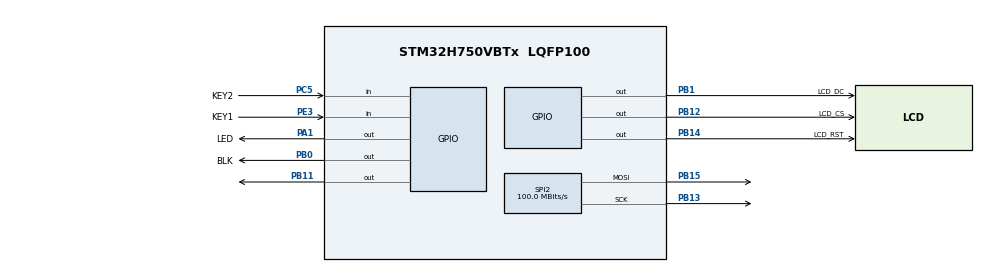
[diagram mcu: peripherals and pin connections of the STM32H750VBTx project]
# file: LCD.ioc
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Mcu.Family=STM32H7
Mcu.Name=STM32H750VBTx
Mcu.Package=LQFP100
NVIC.PriorityGroup=NVIC_PRIORITYGROUP_4
NVIC.SPI2_IRQn=true\:0\:0\:false\:false\:true\:true\:true\:true
PA1.GPIO_Label=LED
PA1.GPIO_ModeDefaultOutputPP=GPIO_MODE_OUTPUT_PP
PA1.GPIO_PuPd=GPIO_PULLUP
PA1.GPIO_Speed=GPIO_SPEED_FREQ_VERY_HIGH
PA1.PinState=GPIO_PIN_SET
PA1.Signal=GPIO_Output
PA13\ (JTMS/SWDIO).Mode=Serial_Wire
PA13\ (JTMS/SWDIO).Signal=DEBUG_JTMS-SWDIO
PA14\ (JTCK/SWCLK).Mode=Serial_Wire
PA14\ (JTCK/SWCLK).Signal=DEBUG_JTCK-SWCLK
PB0.GPIO_Label=BLK
PB0.Signal=GPIO_Output
PB1.GPIO_Label=LCD_DC
PB1.Signal=GPIO_Output
PB11.Signal=GPIO_Output
PB12.GPIO_Label=LCD_CS
PB12.Signal=GPIO_Output
PB13.GPIO_Speed=GPIO_SPEED_FREQ_VERY_HIGH
PB13.Mode=TX_Only_Simplex_Unidirect_Master
PB13.Signal=SPI2_SCK
PB14.GPIO_Label=LCD_RST
PB14.Signal=GPIO_Output
PB15.GPIO_Speed=GPIO_SPEED_FREQ_VERY_HIGH
PB15.Mode=TX_Only_Simplex_Unidirect_Master
PB15.Signal=SPI2_MOSI
PC14-OSC32_IN\ (OSC32_IN).Mode=LSE-External-Oscillator
PC14-OSC32_IN\ (OSC32_IN).Signal=RCC_OSC32_IN
PC15-OSC32_OUT\ (OSC32_OUT).Mode=LSE-External-Oscillator
PC15-OSC32_OUT\ (OSC32_OUT).Signal=RCC_OSC32_OUT
PC5.GPIO_Label=KEY2
PC5.GPIO_PuPd=GPIO_PULLUP
PC5.Signal=GPIO_Input
PE3.GPIO_Label=KEY1
PE3.GPIO_PuPd=GPIO_PULLUP
PE3.Signal=GPIO_Input
PH0-OSC_IN\ (PH0).Mode=HSE-External-Oscillator
PH0-OSC_IN\ (PH0).Signal=RCC_OSC_IN
PH1-OSC_OUT\ (PH1).Mode=HSE-External-Oscillator
PH1-OSC_OUT\ (PH1).Signal=RCC_OSC_OUT
ProjectManager.HeapSize=0x400
ProjectManager.StackSize=0x400
ProjectManager.TargetToolchain=Makefile
RCC.ADCFreq_Value=129000000
RCC.APB1Freq_Value=100000000
RCC.APB2Freq_Value=100000000
RCC.APB3Freq_Value=100000000
RCC.APB4Freq_Value=100000000
RCC.CortexFreq_Value=400000000
RCC.D1PPRE=RCC_APB3_DIV2
RCC.D2PPRE1=RCC_APB1_DIV2
RCC.D2PPRE2=RCC_APB2_DIV2
RCC.D3PPRE=RCC_APB4_DIV2
RCC.DIVM1=4
RCC.DIVN1=50
RCC.DIVQ1=4
RCC.HCLKFreq_Value=200000000
RCC.HPRE=RCC_HCLK_DIV2
RCC.PLL2FRACN=0
RCC.PLL3FRACN=0
RCC.PLLFRACN=0
RCC.PWR_Regulator_Voltage_Scale=PWR_REGULATOR_VOLTAGE_SCALE1
RCC.SYSCLKFreq_VALUE=400000000
RCC.SYSCLKSource=RCC_SYSCLKSOURCE_PLLCLK
RCC.SupplySource=PWR_LDO_SUPPLY
RCC.USBFreq_Value=200000000
SPI2.CLKPhase=SPI_PHASE_2EDGE
SPI2.CLKPolarity=SPI_POLARITY_HIGH
SPI2.CalculateBaudRate=100.0 MBits/s
SPI2.DataSize=SPI_DATASIZE_8BIT
SPI2.Direction=SPI_DIRECTION_2LINES_TXONLY
SPI2.Mode=SPI_MODE_MASTER
SPI2.NSSPMode=SPI_NSS_PULSE_DISABLE
SPI2.VirtualType=VM_MASTER
STMicroelectronics.X-CUBE-DISPLAY.3.0.0_IsPackSelfContextualization=true
board=custom

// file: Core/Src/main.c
/* USER CODE BEGIN Header */
/**
  ******************************************************************************
  * @file           : main.c
  * @brief          : Main program body
  ******************************************************************************
  * @attention
  *
  * Copyright (c) 2023 STMicroelectronics.
  * All rights reserved.
  *
  * This software is licensed under terms that can be found in the LICENSE file
  * in the root directory of this software component.
  * If no LICENSE file comes with this software, it is provided AS-IS.
  *
  ******************************************************************************
  */
/* USER CODE END Header */
#include "main.h"
#include "spi.h"
#include "gpio.h"

/* USER CODE BEGIN Includes */
#include "../../DISPLAY/Lcd_Driver.h"
#include "../../DISPLAY/GUI.h"
/* USER CODE END Includes */

void SystemClock_Config(void);

int main(void)
{

  /* MCU Configuration--------------------------------------------------------*/

  /* Reset of all peripherals, Initializes the Flash interface and the Systick. */
  HAL_Init();

  /* Configure the system clock */
  SystemClock_Config();

  /* Initialize all configured peripherals */
  MX_GPIO_Init();
  MX_SPI2_Init();
  /* USER CODE BEGIN 2 */
    Lcd_Init();
    Lcd_Clear(WHITE);
  /* USER CODE END 2 */

  /* Infinite loop */
  /* USER CODE BEGIN WHILE */
  while (1)
  {

      Mainmenu();
      Num_Test();
      Font_Test();
      Color_Test();
//      show_pic();
//      HAL_Delay(2000);
      show_Circle();
    /* USER CODE END WHILE */

  }
}

void SystemClock_Config(void)
{
  RCC_OscInitTypeDef RCC_OscInitStruct = {0};
  RCC_ClkInitTypeDef RCC_ClkInitStruct = {0};

  /** Supply configuration update enable
  */
  HAL_PWREx_ConfigSupply(PWR_LDO_SUPPLY);

  /** Configure the main internal regulator output voltage
  */
  __HAL_PWR_VOLTAGESCALING_CONFIG(PWR_REGULATOR_VOLTAGE_SCALE1);

  while(!__HAL_PWR_GET_FLAG(PWR_FLAG_VOSRDY)) {}

  /** Initializes the RCC Oscillators according to the specified parameters
  * in the RCC_OscInitTypeDef structure.
  */
  RCC_OscInitStruct.OscillatorType = RCC_OSCILLATORTYPE_HSI;
  RCC_OscInitStruct.HSIState = RCC_HSI_DIV1;
  RCC_OscInitStruct.HSICalibrationValue = RCC_HSICALIBRATION_DEFAULT;
  RCC_OscInitStruct.PLL.PLLState = RCC_PLL_ON;
  RCC_OscInitStruct.PLL.PLLSource = RCC_PLLSOURCE_HSI;
  RCC_OscInitStruct.PLL.PLLM = 4;
  RCC_OscInitStruct.PLL.PLLN = 50;
  RCC_OscInitStruct.PLL.PLLP = 2;
  RCC_OscInitStruct.PLL.PLLQ = 4;
  RCC_OscInitStruct.PLL.PLLR = 2;
  RCC_OscInitStruct.PLL.PLLRGE = RCC_PLL1VCIRANGE_3;
  RCC_OscInitStruct.PLL.PLLVCOSEL = RCC_PLL1VCOWIDE;
  RCC_OscInitStruct.PLL.PLLFRACN = 0;
  if (HAL_RCC_OscConfig(&RCC_OscInitStruct) != HAL_OK)
  {
    Error_Handler();
  }

  /** Initializes the CPU, AHB and APB buses clocks
  */
  RCC_ClkInitStruct.ClockType = RCC_CLOCKTYPE_HCLK|RCC_CLOCKTYPE_SYSCLK
                              |RCC_CLOCKTYPE_PCLK1|RCC_CLOCKTYPE_PCLK2
                              |RCC_CLOCKTYPE_D3PCLK1|RCC_CLOCKTYPE_D1PCLK1;
  RCC_ClkInitStruct.SYSCLKSource = RCC_SYSCLKSOURCE_PLLCLK;
  RCC_ClkInitStruct.SYSCLKDivider = RCC_SYSCLK_DIV1;
  RCC_ClkInitStruct.AHBCLKDivider = RCC_HCLK_DIV2;
  RCC_ClkInitStruct.APB3CLKDivider = RCC_APB3_DIV2;
  RCC_ClkInitStruct.APB1CLKDivider = RCC_APB1_DIV2;
  RCC_ClkInitStruct.APB2CLKDivider = RCC_APB2_DIV2;
  RCC_ClkInitStruct.APB4CLKDivider = RCC_APB4_DIV2;

  if (HAL_RCC_ClockConfig(&RCC_ClkInitStruct, FLASH_LATENCY_2) != HAL_OK)
  {
    Error_Handler();
  }
}

void Error_Handler(void)
{
  __disable_irq();
  while (1)
  {
  }
}
